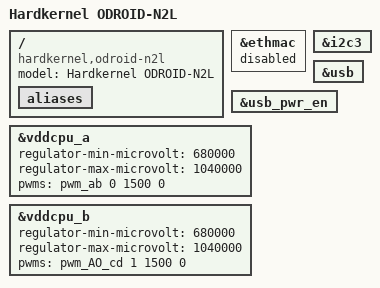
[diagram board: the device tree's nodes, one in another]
// SPDX-License-Identifier: (GPL-2.0+ OR MIT)
/*
 * Copyright (c) 2022 Dongjin Kim <tobetter@gmail.com>
 *
 */

/dts-v1/;

/* The Amlogic S922X Rev. C supports the same OPPs as the A311D variant */
#include "meson-g12b-a311d.dtsi"
#include "meson-g12b-odroid-n2.dtsi"

/ {
	compatible = "hardkernel,odroid-n2l", "amlogic,s922x", "amlogic,g12b";
	model = "Hardkernel ODROID-N2L";

	aliases {
		/delete-property/ rtc0;
	};
};

&ethmac {
	status = "disabled";
};

&i2c3 {
	/delete-node/ rtc@51;
};

&usb {
	/delete-property/ vbus-supply;
};

&usb_pwr_en {
	/delete-property/ gpio;
	/delete-property/ enable-active-high;
};

&vddcpu_a {
	regulator-min-microvolt = <680000>;
	regulator-max-microvolt = <1040000>;

	pwms = <&pwm_ab 0 1500 0>;
};

&vddcpu_b {
	regulator-min-microvolt = <680000>;
	regulator-max-microvolt = <1040000>;

	pwms = <&pwm_AO_cd 1 1500 0>;
};
